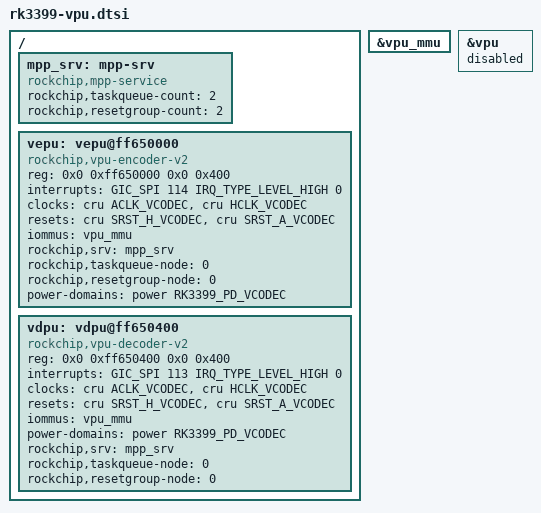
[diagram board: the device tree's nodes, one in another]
/*
 * Rockchip BSP MPP (Media Process Platform) overlay for RK3399.
 *
 * The upstream hantro driver owns the whole combined VPU block at
 * 0xff650000 and does not implement H.264/H.265 encoding. The BSP MPP
 * driver exposes /dev/mpp_service and drives the VEPU2 encoder and
 * VDPU2 decoder that live in the same block. Both drivers cannot be
 * active at the same time, so the mainline vpu node is disabled here.
 *
 * Decoding through the independent VDEC block (rkvdec@ff660000) is not
 * affected and stays enabled.
 */

/ {
	mpp_srv: mpp-srv {
		compatible = "rockchip,mpp-service";
		rockchip,taskqueue-count = <2>;
		rockchip,resetgroup-count = <2>;
		status = "disabled";
	};

	vepu: vepu@ff650000 {
		compatible = "rockchip,vpu-encoder-v2";
		reg = <0x0 0xff650000 0x0 0x400>;
		interrupts = <GIC_SPI 114 IRQ_TYPE_LEVEL_HIGH 0>;
		interrupt-names = "irq_enc";
		clocks = <&cru ACLK_VCODEC>, <&cru HCLK_VCODEC>;
		clock-names = "aclk_vcodec", "hclk_vcodec";
		resets = <&cru SRST_H_VCODEC>, <&cru SRST_A_VCODEC>;
		reset-names = "shared_video_h", "shared_video_a";
		iommus = <&vpu_mmu>;
		rockchip,srv = <&mpp_srv>;
		rockchip,taskqueue-node = <0>;
		rockchip,resetgroup-node = <0>;
		power-domains = <&power RK3399_PD_VCODEC>;
		status = "disabled";
	};

	vdpu: vdpu@ff650400 {
		compatible = "rockchip,vpu-decoder-v2";
		reg = <0x0 0xff650400 0x0 0x400>;
		interrupts = <GIC_SPI 113 IRQ_TYPE_LEVEL_HIGH 0>;
		interrupt-names = "irq_dec";
		clocks = <&cru ACLK_VCODEC>, <&cru HCLK_VCODEC>;
		clock-names = "aclk_vcodec", "hclk_vcodec";
		resets = <&cru SRST_H_VCODEC>, <&cru SRST_A_VCODEC>;
		reset-names = "shared_video_h", "shared_video_a";
		iommus = <&vpu_mmu>;
		power-domains = <&power RK3399_PD_VCODEC>;
		rockchip,srv = <&mpp_srv>;
		rockchip,taskqueue-node = <0>;
		rockchip,resetgroup-node = <0>;
		status = "disabled";
	};
};

&mpp_srv {
	status = "okay";
};

&vepu {
	status = "okay";
};

&vdpu {
	status = "okay";
};

&vpu_mmu {
	status = "okay";
};

/* Mainline hantro driver: no encoder support and conflicts with MPP. */
&vpu {
	status = "disabled";
};
